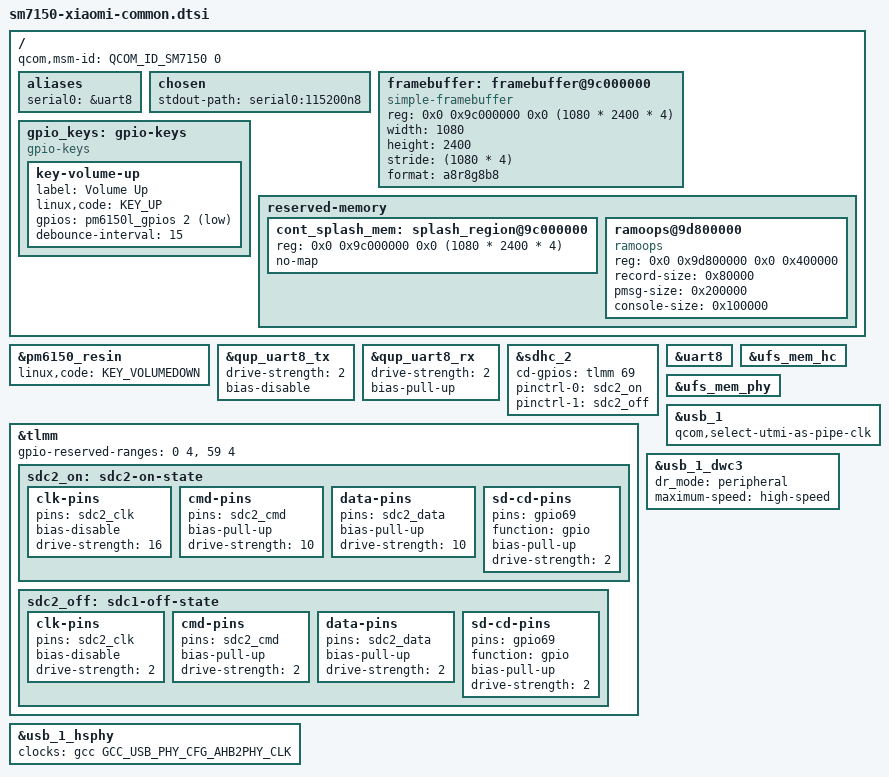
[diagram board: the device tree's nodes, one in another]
// SPDX-License-Identifier: BSD-3-Clause
/*
 * Xiaomi common board device tree source
 *
 * (C) Copyright 2024 Danila Tikhonov <danila@jiaxyga.com>
 */

/dts-v1/;

#include <dt-bindings/arm/qcom,ids.h>
#include <dt-bindings/firmware/qcom,scm.h>
#include <dt-bindings/gpio/gpio.h>
#include <dt-bindings/input/linux-event-codes.h>

#include "sm7150.dtsi"
#include "pm6150.dtsi"
#include "pm6150l.dtsi"

/ {
	qcom,msm-id = <QCOM_ID_SM7150 0>;

	aliases {
		serial0 = &uart8;
	};

	chosen {
		stdout-path = "serial0:115200n8";
	};

	framebuffer: framebuffer@9c000000 {
		compatible = "simple-framebuffer";
		reg = <0x0 0x9c000000 0x0 (1080 * 2400 * 4)>;
		width = <1080>;
		height = <2400>;
		stride = <(1080 * 4)>;
		format = "a8r8g8b8";
	};

	gpio_keys: gpio-keys {
		compatible = "gpio-keys";

		key-volume-up {
			label = "Volume Up";
			linux,code = <KEY_UP>; /* KEY_VOLUMEUP */
			gpios = <&pm6150l_gpios 2 GPIO_ACTIVE_LOW>;
			debounce-interval = <15>;
		};
	};

	reserved-memory {
		cont_splash_mem: splash_region@9c000000 {
			reg = <0x0 0x9c000000 0x0 (1080 * 2400 * 4)>;
			no-map;
		};

		ramoops@9d800000 {
			compatible = "ramoops";
			reg = <0x0 0x9d800000 0x0 0x400000>;

			record-size = <0x80000>;
			pmsg-size = <0x200000>;
			console-size = <0x100000>;
		};
	};
};

&pm6150_resin {
	linux,code = <KEY_VOLUMEDOWN>;
	status = "okay";
};

&qup_uart8_tx {
	drive-strength = <2>;
	bias-disable;
};

&qup_uart8_rx {
	drive-strength = <2>;
	bias-pull-up;
};

&sdhc_2 {
	cd-gpios = <&tlmm 69 GPIO_ACTIVE_HIGH>;

	pinctrl-names = "default", "sleep";
	pinctrl-0 = <&sdc2_on>;
	pinctrl-1 = <&sdc2_off>;
};

&tlmm {
	/* Reserved I/Os for NFC and FP */
	gpio-reserved-ranges = <0 4>, <59 4>;

	sdc2_on: sdc2-on-state {
		clk-pins {
			pins = "sdc2_clk";
			bias-disable;
			drive-strength = <16>;
		};

		cmd-pins {
			pins = "sdc2_cmd";
			bias-pull-up;
			drive-strength = <10>;
		};

		data-pins {
			pins = "sdc2_data";
			bias-pull-up;
			drive-strength = <10>;
		};

		sd-cd-pins {
			pins = "gpio69";
			function = "gpio";
			bias-pull-up;
			drive-strength = <2>;
		};
	};

	sdc2_off: sdc1-off-state {
		clk-pins {
			pins = "sdc2_clk";
			bias-disable;
			drive-strength = <2>;
		};

		cmd-pins {
			pins = "sdc2_cmd";
			bias-pull-up;
			drive-strength = <2>;
		};

		data-pins {
			pins = "sdc2_data";
			bias-pull-up;
			drive-strength = <2>;
		};

		sd-cd-pins {
			pins = "gpio69";
			function = "gpio";
			bias-pull-up;
			drive-strength = <2>;
		};
	};
};

&uart8 {
	status = "okay";
};

&ufs_mem_hc {
	status = "okay";
};

&ufs_mem_phy {
	status = "okay";
};

&usb_1 {
	qcom,select-utmi-as-pipe-clk;
	status = "okay";
};

&usb_1_dwc3 {
	dr_mode = "peripheral";
	maximum-speed = "high-speed";
};

&usb_1_hsphy {
	/* Remove ref clk because rmphcc isn't available */
	clocks = <&gcc GCC_USB_PHY_CFG_AHB2PHY_CLK>;
	clock-names = "cfg_ahb";

	status = "okay";
};
